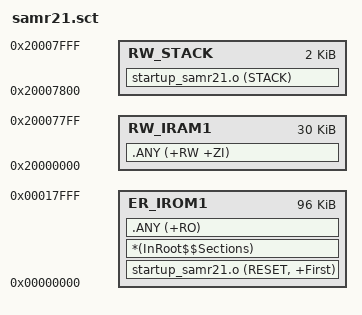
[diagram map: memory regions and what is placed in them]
LR_IROM1 0x00000000 0x00018000 {
  ER_IROM1 0x00000000 0x00018000 {
    startup_samr21.o (RESET, +First)
    *(InRoot$$Sections)
    .ANY (+RO)
  }
  RW_IRAM1 0x20000000 0x00007800 {
    .ANY (+RW +ZI)
  }
  RW_STACK 0x20007800 0x00000800 {
    startup_samr21.o (STACK)
  }
}
